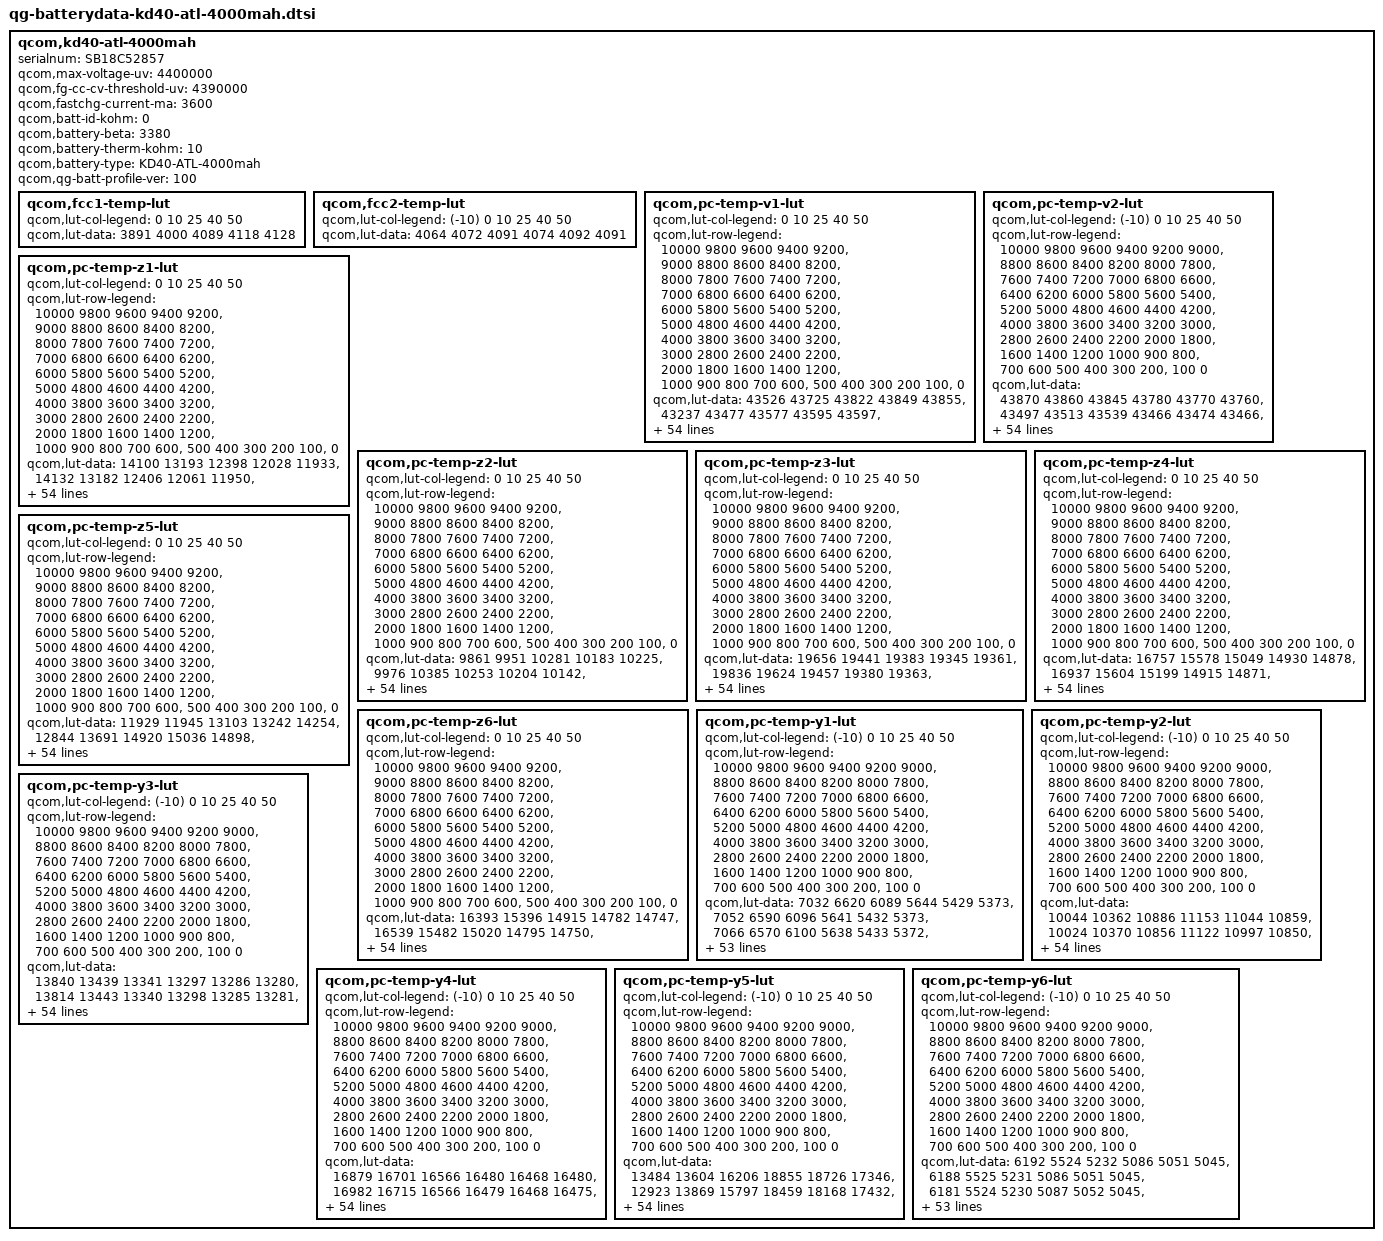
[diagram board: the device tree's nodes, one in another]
// SPDX-License-Identifier: GPL-2.0
/*
 * Copyright (c) 2018-2019, The Linux Foundation. All rights reserved.
 */

qcom,kd40-atl-4000mah {
	serialnum = "SB18C52857";
	qcom,max-voltage-uv = <4400000>;
	qcom,fg-cc-cv-threshold-uv = <4390000>;
	qcom,fastchg-current-ma = <3600>;
	qcom,batt-id-kohm = <0>;
	qcom,battery-beta = <3380>;
	qcom,battery-therm-kohm = <10>;
	qcom,battery-type = "KD40-ATL-4000mah";
	qcom,qg-batt-profile-ver = <100>;

	qcom,fcc1-temp-lut {
		qcom,lut-col-legend = <0 10 25 40 50>;
		qcom,lut-data = <3891 4000 4089 4118 4128>;
	};

	qcom,fcc2-temp-lut {
		qcom,lut-col-legend = <(-10) 0 10 25 40 50>;
		qcom,lut-data = <4064 4072 4091 4074 4092 4091>;
	};

	qcom,pc-temp-v1-lut {
		qcom,lut-col-legend = <0 10 25 40 50>;
		qcom,lut-row-legend = <10000 9800 9600 9400 9200>,
			<9000 8800 8600 8400 8200>,
			<8000 7800 7600 7400 7200>,
			<7000 6800 6600 6400 6200>,
			<6000 5800 5600 5400 5200>,
			<5000 4800 4600 4400 4200>,
			<4000 3800 3600 3400 3200>,
			<3000 2800 2600 2400 2200>,
			<2000 1800 1600 1400 1200>,
			<1000 900 800 700 600>,
			<500 400 300 200 100>,
			<0>;
		qcom,lut-data = <43526 43725 43822 43849 43855>,
			<43237 43477 43577 43595 43597>,
			<42977 43205 43334 43357 43363>,
			<42736 42949 43094 43119 43127>,
			<42502 42711 42852 42882 42892>,
			<42270 42477 42606 42643 42656>,
			<42044 42244 42365 42406 42422>,
			<41823 42013 42129 42172 42189>,
			<41606 41788 41900 41943 41959>,
			<41400 41567 41673 41717 41733>,
			<41218 41355 41449 41492 41510>,
			<41042 41166 41234 41274 41292>,
			<40834 40983 41033 41065 41076>,
			<40577 40773 40836 40865 40865>,
			<40330 40526 40626 40661 40660>,
			<40130 40297 40408 40450 40462>,
			<39954 40111 40210 40252 40272>,
			<39800 39945 40038 40078 40097>,
			<39670 39795 39877 39916 39931>,
			<39548 39661 39728 39758 39769>,
			<39423 39526 39587 39608 39617>,
			<39298 39386 39407 39433 39445>,
			<39175 39240 39148 39173 39197>,
			<39054 39066 38908 38916 38943>,
			<38936 38848 38752 38772 38793>,
			<38825 38663 38630 38673 38691>,
			<38719 38539 38533 38581 38596>,
			<38620 38442 38458 38491 38502>,
			<38526 38374 38390 38406 38412>,
			<38439 38323 38322 38326 38323>,
			<38365 38279 38259 38251 38238>,
			<38299 38236 38202 38182 38164>,
			<38245 38197 38151 38119 38102>,
			<38203 38160 38102 38061 38042>,
			<38169 38126 38058 38008 37982>,
			<38135 38092 38016 37959 37924>,
			<38104 38060 37975 37909 37865>,
			<38068 38024 37936 37861 37810>,
			<38018 37972 37884 37800 37744>,
			<37951 37889 37802 37714 37653>,
			<37867 37790 37700 37610 37546>,
			<37750 37679 37588 37500 37432>,
			<37616 37549 37459 37376 37304>,
			<37470 37391 37306 37220 37151>,
			<37335 37251 37167 37080 37017>,
			<37241 37154 37073 36994 36937>,
			<37202 37127 37043 36964 36910>,
			<37177 37111 37028 36946 36889>,
			<37148 37085 37007 36924 36864>,
			<37094 37035 36949 36850 36778>,
			<36866 36788 36689 36570 36473>,
			<36421 36348 36254 36124 36028>,
			<35836 35772 35680 35546 35448>,
			<35041 34986 34894 34755 34655>,
			<33786 33750 33659 33524 33419>,
			<30000 30000 30000 30000 30000>;
	};

	qcom,pc-temp-v2-lut {
		qcom,lut-col-legend = <(-10) 0 10 25 40 50>;
		qcom,lut-row-legend = <10000 9800 9600 9400 9200 9000>,
			<8800 8600 8400 8200 8000 7800>,
			<7600 7400 7200 7000 6800 6600>,
			<6400 6200 6000 5800 5600 5400>,
			<5200 5000 4800 4600 4400 4200>,
			<4000 3800 3600 3400 3200 3000>,
			<2800 2600 2400 2200 2000 1800>,
			<1600 1400 1200 1000 900 800>,
			<700 600 500 400 300 200>,
			<100 0>;
		qcom,lut-data = <43870 43860 43845 43780 43770 43760>,
			<43497 43513 43539 43466 43474 43466>,
			<43156 43197 43252 43174 43196 43190>,
			<42853 42915 42986 42910 42937 42934>,
			<42582 42665 42741 42669 42697 42696>,
			<42329 42423 42502 42434 42462 42461>,
			<42094 42181 42267 42199 42226 42227>,
			<41869 41946 42035 41966 41993 41994>,
			<41626 41723 41805 41737 41764 41765>,
			<41370 41509 41578 41511 41538 41539>,
			<41148 41297 41358 41291 41316 41316>,
			<40983 41089 41146 41077 41099 41097>,
			<40816 40877 40939 40867 40886 40883>,
			<40563 40652 40736 40662 40682 40679>,
			<40227 40414 40534 40458 40483 40481>,
			<39926 40163 40315 40260 40289 40289>,
			<39661 39877 40068 40063 40096 40101>,
			<39436 39616 39826 39878 39913 39922>,
			<39276 39432 39611 39722 39750 39758>,
			<39148 39283 39409 39577 39596 39599>,
			<39018 39130 39224 39397 39412 39417>,
			<38884 38969 39049 39153 39189 39201>,
			<38746 38817 38891 38923 38977 38995>,
			<38582 38678 38748 38755 38795 38809>,
			<38409 38549 38618 38614 38633 38641>,
			<38280 38428 38499 38490 38502 38506>,
			<38184 38314 38388 38383 38394 38396>,
			<38103 38208 38286 38285 38297 38297>,
			<38031 38104 38193 38195 38209 38208>,
			<37966 38010 38105 38112 38129 38127>,
			<37907 37941 38024 38039 38057 38053>,
			<37853 37888 37947 37971 37992 37984>,
			<37799 37842 37881 37911 37927 37918>,
			<37742 37802 37823 37855 37863 37857>,
			<37685 37765 37773 37803 37796 37791>,
			<37630 37726 37731 37745 37717 37701>,
			<37575 37688 37694 37683 37630 37592>,
			<37519 37640 37651 37618 37545 37492>,
			<37460 37570 37601 37551 37466 37404>,
			<37400 37488 37540 37479 37385 37319>,
			<37343 37405 37460 37400 37305 37239>,
			<37286 37314 37360 37311 37217 37154>,
			<37220 37214 37247 37194 37102 37037>,
			<37146 37111 37116 37064 36977 36912>,
			<37064 37008 36982 36942 36867 36808>,
			<36955 36903 36912 36884 36819 36763>,
			<36892 36857 36884 36868 36808 36752>,
			<36826 36809 36862 36850 36791 36733>,
			<36740 36747 36824 36820 36757 36697>,
			<36591 36641 36728 36737 36651 36570>,
			<36335 36400 36449 36449 36312 36201>,
			<35925 35965 35938 35973 35815 35692>,
			<35315 35339 35271 35348 35169 35039>,
			<34402 34453 34364 34527 34288 34145>,
			<32972 33049 33061 33271 32993 32824>,
			<28326 27783 27914 28055 27759 27662>;
	};

	qcom,pc-temp-z1-lut {
		qcom,lut-col-legend = <0 10 25 40 50>;
		qcom,lut-row-legend = <10000 9800 9600 9400 9200>,
			<9000 8800 8600 8400 8200>,
			<8000 7800 7600 7400 7200>,
			<7000 6800 6600 6400 6200>,
			<6000 5800 5600 5400 5200>,
			<5000 4800 4600 4400 4200>,
			<4000 3800 3600 3400 3200>,
			<3000 2800 2600 2400 2200>,
			<2000 1800 1600 1400 1200>,
			<1000 900 800 700 600>,
			<500 400 300 200 100>,
			<0>;
		qcom,lut-data = <14100 13193 12398 12028 11933>,
			<14132 13182 12406 12061 11950>,
			<14132 13183 12404 12055 11954>,
			<14108 13182 12394 12054 11953>,
			<14089 13171 12386 12052 11952>,
			<14070 13159 12377 12049 11952>,
			<14051 13154 12370 12047 11951>,
			<14046 13148 12362 12046 11952>,
			<14050 13141 12356 12046 11955>,
			<14055 13125 12356 12046 11958>,
			<14054 13110 12358 12048 11959>,
			<14050 13102 12359 12050 11960>,
			<14033 13097 12359 12051 11961>,
			<13967 13085 12358 12052 11963>,
			<13912 13061 12356 12052 11963>,
			<13911 13047 12352 12052 11963>,
			<13919 13050 12351 12051 11963>,
			<13917 13057 12354 12052 11965>,
			<13891 13061 12358 12054 11967>,
			<13869 13066 12362 12056 11969>,
			<13868 13072 12366 12058 11970>,
			<13869 13079 12369 12059 11970>,
			<13871 13089 12372 12060 11972>,
			<13877 13099 12376 12060 11973>,
			<13886 13112 12380 12062 11975>,
			<13894 13122 12385 12065 11976>,
			<13902 13129 12391 12069 11979>,
			<13908 13134 12397 12073 11982>,
			<13913 13136 12403 12077 11986>,
			<13918 13137 12408 12080 11989>,
			<13924 13137 12413 12084 11992>,
			<13935 13145 12418 12088 11996>,
			<13944 13158 12423 12093 12000>,
			<13951 13165 12429 12098 12004>,
			<13960 13169 12437 12102 12008>,
			<13970 13174 12447 12107 12012>,
			<14004 13186 12455 12112 12016>,
			<14035 13204 12462 12118 12019>,
			<14036 13214 12470 12122 12023>,
			<14032 13222 12477 12126 12027>,
			<14030 13229 12485 12129 12031>,
			<14045 13240 12493 12134 12033>,
			<14056 13249 12502 12138 12036>,
			<14077 13259 12509 12142 12038>,
			<14047 13282 12518 12146 12041>,
			<14053 13276 12521 12149 12044>,
			<14120 13285 12520 12150 12044>,
			<14113 13278 12521 12152 12044>,
			<14057 13280 12524 12154 12048>,
			<14057 13288 12534 12159 12054>,
			<14047 13284 12539 12164 12058>,
			<14077 13321 12547 12173 12066>,
			<14138 13357 12569 12187 12078>,
			<14107 13404 12602 12207 12096>,
			<14107 13404 12602 12207 12096>,
			<14107 13404 12602 12207 12096>;
	};

	qcom,pc-temp-z2-lut {
		qcom,lut-col-legend = <0 10 25 40 50>;
		qcom,lut-row-legend = <10000 9800 9600 9400 9200>,
			<9000 8800 8600 8400 8200>,
			<8000 7800 7600 7400 7200>,
			<7000 6800 6600 6400 6200>,
			<6000 5800 5600 5400 5200>,
			<5000 4800 4600 4400 4200>,
			<4000 3800 3600 3400 3200>,
			<3000 2800 2600 2400 2200>,
			<2000 1800 1600 1400 1200>,
			<1000 900 800 700 600>,
			<500 400 300 200 100>,
			<0>;
		qcom,lut-data = <9861 9951 10281 10183 10225>,
			<9976 10385 10253 10204 10142>,
			<10039 10206 10502 10300 10221>,
			<10084 10122 10779 10319 10280>,
			<10098 10099 10809 10324 10313>,
			<10087 10085 10494 10319 10302>,
			<10071 10080 10241 10307 10277>,
			<10065 10077 10209 10283 10256>,
			<10062 10073 10191 10242 10233>,
			<10060 10065 10189 10225 10215>,
			<10060 10059 10198 10234 10199>,
			<10059 10087 10215 10242 10186>,
			<10055 10148 10360 10205 10189>,
			<10042 10159 10542 10128 10207>,
			<10030 10103 10515 10110 10206>,
			<10025 10056 10322 10147 10178>,
			<10022 10067 10232 10172 10158>,
			<10022 10090 10242 10152 10144>,
			<10036 10112 10256 10127 10118>,
			<10051 10137 10269 10136 10117>,
			<10055 10158 10289 10165 10134>,
			<10056 10172 10316 10206 10159>,
			<10054 10183 10366 10312 10232>,
			<10037 10197 10401 10413 10316>,
			<10018 10217 10380 10372 10308>,
			<10016 10230 10336 10227 10240>,
			<10017 10232 10320 10172 10210>,
			<10019 10233 10314 10191 10229>,
			<10025 10231 10313 10220 10261>,
			<10032 10226 10326 10259 10305>,
			<10039 10222 10348 10304 10362>,
			<10046 10222 10354 10320 10366>,
			<10053 10223 10357 10324 10269>,
			<10058 10225 10359 10324 10180>,
			<10063 10230 10367 10305 10146>,
			<10071 10236 10378 10280 10122>,
			<10087 10245 10385 10279 10134>,
			<10105 10256 10391 10296 10187>,
			<10119 10267 10400 10317 10233>,
			<10132 10279 10420 10347 10260>,
			<10146 10289 10442 10374 10281>,
			<10160 10296 10455 10374 10294>,
			<10182 10303 10464 10363 10303>,
			<10230 10313 10447 10398 10283>,
			<10402 10415 10461 10406 10263>,
			<10293 10524 10508 10338 10253>,
			<10302 10558 10499 10320 10265>,
			<10292 10713 10500 10339 10269>,
			<10278 10727 10534 10359 10300>,
			<10218 10834 10559 10405 10334>,
			<10205 10760 10578 10367 10183>,
			<10099 10688 10526 10207 10063>,
			<9986 10508 10507 10157 10009>,
			<9834 10354 10442 10097 9939>,
			<9834 10354 10442 10097 9939>,
			<9834 10354 10442 10097 9939>;
	};

	qcom,pc-temp-z3-lut {
		qcom,lut-col-legend = <0 10 25 40 50>;
		qcom,lut-row-legend = <10000 9800 9600 9400 9200>,
			<9000 8800 8600 8400 8200>,
			<8000 7800 7600 7400 7200>,
			<7000 6800 6600 6400 6200>,
			<6000 5800 5600 5400 5200>,
			<5000 4800 4600 4400 4200>,
			<4000 3800 3600 3400 3200>,
			<3000 2800 2600 2400 2200>,
			<2000 1800 1600 1400 1200>,
			<1000 900 800 700 600>,
			<500 400 300 200 100>,
			<0>;
		qcom,lut-data = <19656 19441 19383 19345 19361>,
			<19836 19624 19457 19380 19363>,
			<19840 19689 19482 19412 19397>,
			<19801 19699 19495 19423 19413>,
			<19769 19701 19499 19432 19422>,
			<19746 19701 19501 19442 19430>,
			<19731 19701 19502 19449 19435>,
			<19729 19700 19500 19448 19436>,
			<19730 19696 19497 19445 19436>,
			<19731 19685 19493 19441 19435>,
			<19731 19674 19484 19434 19427>,
			<19731 19668 19478 19425 19416>,
			<19733 19666 19481 19413 19412>,
			<19743 19664 19489 19399 19409>,
			<19751 19647 19486 19396 19406>,
			<19748 19628 19471 19400 19401>,
			<19738 19607 19459 19402 19395>,
			<19723 19583 19449 19397 19387>,
			<19693 19570 19440 19388 19377>,
			<19668 19559 19435 19382 19370>,
			<19668 19554 19431 19377 19365>,
			<19675 19558 19431 19375 19363>,
			<19685 19567 19451 19385 19368>,
			<19719 19579 19467 19396 19376>,
			<19759 19599 19463 19390 19370>,
			<19777 19612 19452 19368 19347>,
			<19787 19611 19444 19360 19337>,
			<19792 19610 19437 19360 19343>,
			<19793 19608 19434 19360 19354>,
			<19793 19602 19435 19367 19373>,
			<19792 19595 19438 19381 19399>,
			<19787 19589 19440 19392 19406>,
			<19779 19582 19443 19400 19399>,
			<19767 19577 19446 19404 19391>,
			<19751 19574 19447 19401 19384>,
			<19734 19569 19448 19394 19377>,
			<19711 19562 19446 19389 19371>,
			<19692 19553 19439 19383 19366>,
			<19683 19550 19434 19379 19362>,
			<19678 19551 19431 19375 19358>,
			<19674 19550 19429 19373 19355>,
			<19670 19542 19426 19371 19357>,
			<19664 19531 19424 19370 19364>,
			<19636 19527 19421 19374 19369>,
			<19519 19497 19410 19374 19368>,
			<19357 19466 19394 19358 19352>,
			<19350 19446 19394 19358 19342>,
			<19324 19356 19372 19350 19337>,
			<19323 19383 19366 19344 19330>,
			<19314 19344 19359 19339 19333>,
			<19324 19366 19365 19352 19369>,
			<19330 19378 19363 19366 19369>,
			<19358 19361 19352 19367 19372>,
			<19364 19353 19352 19368 19372>,
			<19364 19353 19352 19368 19372>,
			<19364 19353 19352 19368 19372>;
	};

	qcom,pc-temp-z4-lut {
		qcom,lut-col-legend = <0 10 25 40 50>;
		qcom,lut-row-legend = <10000 9800 9600 9400 9200>,
			<9000 8800 8600 8400 8200>,
			<8000 7800 7600 7400 7200>,
			<7000 6800 6600 6400 6200>,
			<6000 5800 5600 5400 5200>,
			<5000 4800 4600 4400 4200>,
			<4000 3800 3600 3400 3200>,
			<3000 2800 2600 2400 2200>,
			<2000 1800 1600 1400 1200>,
			<1000 900 800 700 600>,
			<500 400 300 200 100>,
			<0>;
		qcom,lut-data = <16757 15578 15049 14930 14878>,
			<16937 15604 15199 14915 14871>,
			<16865 15563 15167 14976 14916>,
			<16580 15498 15046 14932 14889>,
			<16311 15349 14974 14888 14857>,
			<16108 15202 14933 14854 14832>,
			<15927 15108 14899 14825 14808>,
			<15780 15032 14867 14802 14786>,
			<15654 14976 14837 14783 14765>,
			<15548 14935 14812 14769 14751>,
			<15460 14899 14791 14756 14744>,
			<15384 14854 14771 14748 14738>,
			<15322 14808 14741 14745 14731>,
			<15272 14789 14714 14743 14723>,
			<15225 14792 14712 14739 14718>,
			<15177 14799 14726 14730 14714>,
			<15131 14796 14731 14720 14711>,
			<15098 14788 14723 14712 14707>,
			<15077 14780 14713 14703 14704>,
			<15057 14766 14705 14700 14701>,
			<15029 14752 14697 14698 14698>,
			<14993 14739 14700 14698 14696>,
			<14954 14729 14758 14761 14753>,
			<14904 14735 14817 14840 14834>,
			<14858 14784 14837 14855 14854>,
			<14835 14821 14850 14860 14860>,
			<14820 14829 14851 14860 14861>,
			<14812 14833 14836 14847 14842>,
			<14809 14831 14818 14826 14810>,
			<14808 14815 14801 14801 14775>,
			<14807 14797 14782 14771 14734>,
			<14805 14783 14764 14746 14714>,
			<14804 14770 14746 14723 14705>,
			<14802 14758 14731 14709 14700>,
			<14800 14747 14718 14704 14699>,
			<14799 14738 14708 14701 14698>,
			<14801 14731 14703 14700 14698>,
			<14802 14725 14700 14699 14699>,
			<14798 14723 14699 14699 14700>,
			<14784 14722 14704 14710 14712>,
			<14775 14721 14710 14722 14727>,
			<14770 14724 14707 14720 14723>,
			<14767 14726 14702 14712 14710>,
			<14770 14722 14703 14710 14711>,
			<14810 14711 14697 14704 14707>,
			<14934 14701 14678 14683 14683>,
			<14936 14713 14669 14674 14681>,
			<14956 14807 14679 14663 14667>,
			<14950 14766 14672 14647 14645>,
			<14948 14804 14679 14650 14641>,
			<14940 14794 14696 14677 14658>,
			<14962 14796 14711 14678 14672>,
			<14957 14826 14729 14683 14674>,
			<14977 14850 14736 14686 14678>,
			<14977 14850 14736 14686 14678>,
			<14977 14850 14736 14686 14678>;
	};

	qcom,pc-temp-z5-lut {
		qcom,lut-col-legend = <0 10 25 40 50>;
		qcom,lut-row-legend = <10000 9800 9600 9400 9200>,
			<9000 8800 8600 8400 8200>,
			<8000 7800 7600 7400 7200>,
			<7000 6800 6600 6400 6200>,
			<6000 5800 5600 5400 5200>,
			<5000 4800 4600 4400 4200>,
			<4000 3800 3600 3400 3200>,
			<3000 2800 2600 2400 2200>,
			<2000 1800 1600 1400 1200>,
			<1000 900 800 700 600>,
			<500 400 300 200 100>,
			<0>;
		qcom,lut-data = <11929 11945 13103 13242 14254>,
			<12844 13691 14920 15036 14898>,
			<13167 14619 15415 16148 16503>,
			<13323 15060 15769 16769 17691>,
			<13484 15307 16141 17420 18689>,
			<13691 15570 16687 18414 19595>,
			<13895 16064 17187 19279 20420>,
			<14068 16649 17559 19596 21280>,
			<14225 17095 17911 19780 22214>,
			<14356 17444 18222 19863 22571>,
			<14457 17687 18656 20003 22189>,
			<14542 18545 19324 20120 21754>,
			<14632 20063 22055 19598 21968>,
			<14749 20649 25238 18434 22768>,
			<14830 20927 25018 18383 23389>,
			<14843 20801 22389 20254 23859>,
			<14848 19870 21144 21690 24119>,
			<14823 18764 21267 21672 23572>,
			<14508 18660 21502 21493 22496>,
			<14199 19110 22072 21783 22303>,
			<14271 19829 23496 22354 22756>,
			<14675 21769 26712 23310 23435>,
			<15324 25594 39639 27194 24922>,
			<17153 31801 49817 31251 26468>,
			<19789 44390 44871 29094 24879>,
			<22249 52101 33750 21259 18519>,
			<24810 50038 27699 17431 15638>,
			<27197 45580 24122 16554 15586>,
			<29693 41641 22559 16160 15586>,
			<31762 37728 22549 16618 17376>,
			<32162 34567 22576 18014 21820>,
			<32160 32310 22879 19903 23895>,
			<32149 30636 24322 23163 24705>,
			<30993 30047 26255 25996 25074>,
			<28176 29839 29703 27726 25805>,
			<25646 29619 32873 28920 26965>,
			<23052 28760 32988 29050 27100>,
			<21319 27595 32175 28876 26936>,
			<21380 27627 31271 28573 26626>,
			<22002 29375 30325 27037 24497>,
			<22731 30602 29304 24874 22087>,
			<23985 27907 28165 23210 22035>,
			<24571 25036 27024 21945 22674>,
			<22842 25692 25695 23169 23855>,
			<18316 24770 24858 23834 24141>,
			<12477 22683 23349 21022 20529>,
			<12345 19724 23506 21214 18173>,
			<11899 13085 18416 20206 18412>,
			<11878 14716 17908 21181 20274>,
			<11802 12901 17087 19879 21423>,
			<12018 13676 17002 17829 23841>,
			<11930 13781 15606 18088 19764>,
			<12141 12873 14253 17108 18434>,
			<11942 12386 13854 16243 16818>,
			<11942 12386 13854 16243 16818>,
			<11942 12386 13854 16243 16818>;
	};

	qcom,pc-temp-z6-lut {
		qcom,lut-col-legend = <0 10 25 40 50>;
		qcom,lut-row-legend = <10000 9800 9600 9400 9200>,
			<9000 8800 8600 8400 8200>,
			<8000 7800 7600 7400 7200>,
			<7000 6800 6600 6400 6200>,
			<6000 5800 5600 5400 5200>,
			<5000 4800 4600 4400 4200>,
			<4000 3800 3600 3400 3200>,
			<3000 2800 2600 2400 2200>,
			<2000 1800 1600 1400 1200>,
			<1000 900 800 700 600>,
			<500 400 300 200 100>,
			<0>;
		qcom,lut-data = <16393 15396 14915 14782 14747>,
			<16539 15482 15020 14795 14750>,
			<16502 15491 15013 14834 14785>,
			<16340 15480 14971 14823 14782>,
			<16189 15406 14943 14811 14777>,
			<16078 15329 14924 14801 14771>,
			<15982 15283 14908 14793 14764>,
			<15907 15244 14892 14783 14756>,
			<15846 15213 14876 14774 14749>,
			<15795 15186 14862 14765 14742>,
			<15753 15162 14849 14756 14734>,
			<15716 15139 14838 14748 14726>,
			<15680 15118 14828 14740 14720>,
			<15645 15101 14820 14732 14715>,
			<15612 15087 14815 14728 14711>,
			<15583 15074 14812 14725 14706>,
			<15557 15061 14807 14722 14702>,
			<15532 15049 14799 14715 14695>,
			<15506 15038 14790 14707 14688>,
			<15485 15028 14784 14702 14683>,
			<15470 15023 14780 14698 14679>,
			<15458 15023 14782 14698 14677>,
			<15454 15024 14819 14731 14705>,
			<15455 15031 14852 14771 14745>,
			<15457 15064 14856 14773 14748>,
			<15459 15089 14858 14766 14742>,
			<15461 15094 14857 14760 14735>,
			<15463 15097 14849 14754 14730>,
			<15465 15096 14839 14748 14724>,
			<15467 15088 14833 14743 14721>,
			<15467 15079 14828 14738 14717>,
			<15467 15072 14823 14733 14713>,
			<15465 15065 14817 14728 14707>,
			<15462 15060 14813 14724 14700>,
			<15455 15056 14810 14721 14696>,
			<15449 15053 14808 14717 14692>,
			<15443 15049 14804 14714 14689>,
			<15439 15046 14801 14710 14686>,
			<15436 15046 14799 14709 14685>,
			<15435 15051 14801 14712 14689>,
			<15434 15054 14804 14716 14693>,
			<15436 15054 14803 14714 14693>,
			<15437 15054 14801 14711 14692>,
			<15432 15054 14801 14713 14694>,
			<15396 15042 14795 14711 14692>,
			<15374 15026 14780 14694 14674>,
			<15370 15022 14777 14690 14669>,
			<15366 15016 14770 14681 14660>,
			<15365 15014 14764 14671 14647>,
			<15365 15015 14765 14671 14647>,
			<15378 15028 14777 14691 14674>,
			<15400 15043 14787 14701 14684>,
			<15430 15059 14793 14707 14689>,
			<15468 15084 14804 14714 14696>,
			<15468 15084 14804 14714 14696>,
			<15468 15084 14804 14714 14696>;
	};

	qcom,pc-temp-y1-lut {
		qcom,lut-col-legend = <(-10) 0 10 25 40 50>;
		qcom,lut-row-legend = <10000 9800 9600 9400 9200 9000>,
			<8800 8600 8400 8200 8000 7800>,
			<7600 7400 7200 7000 6800 6600>,
			<6400 6200 6000 5800 5600 5400>,
			<5200 5000 4800 4600 4400 4200>,
			<4000 3800 3600 3400 3200 3000>,
			<2800 2600 2400 2200 2000 1800>,
			<1600 1400 1200 1000 900 800>,
			<700 600 500 400 300 200>,
			<100 0>;
		qcom,lut-data = <7032 6620 6089 5644 5429 5373>,
			<7052 6590 6096 5641 5432 5373>,
			<7066 6570 6100 5638 5433 5372>,
			<7077 6558 6101 5635 5433 5372>,
			<7083 6553 6099 5633 5433 5372>,
			<7084 6551 6095 5630 5433 5371>,
			<7079 6549 6087 5628 5431 5371>,
			<7072 6546 6078 5626 5429 5371>,
			<7075 6543 6077 5624 5428 5371>,
			<7088 6540 6077 5622 5427 5369>,
			<7096 6537 6075 5621 5427 5368>,
			<7100 6531 6065 5620 5427 5369>,
			<7102 6524 6055 5619 5427 5370>,
			<7105 6520 6055 5619 5427 5370>,
			<7112 6517 6058 5618 5427 5370>,
			<7114 6519 6059 5618 5427 5370>,
			<7115 6533 6060 5620 5430 5371>,
			<7115 6546 6062 5623 5432 5372>,
			<7111 6542 6067 5625 5432 5372>,
			<7106 6533 6075 5627 5433 5373>,
			<7110 6530 6075 5629 5433 5373>,
			<7120 6534 6068 5633 5433 5374>,
			<7127 6538 6063 5636 5434 5375>,
			<7123 6539 6068 5640 5435 5377>,
			<7111 6540 6077 5644 5437 5379>,
			<7099 6542 6081 5648 5440 5382>,
			<7085 6557 6080 5653 5444 5385>,
			<7074 6567 6080 5658 5447 5387>,
			<7072 6558 6080 5663 5450 5389>,
			<7072 6543 6081 5669 5454 5391>,
			<7070 6540 6084 5673 5457 5393>,
			<7067 6548 6091 5677 5460 5397>,
			<7063 6552 6098 5682 5463 5399>,
			<7057 6545 6108 5686 5466 5402>,
			<7051 6535 6115 5690 5469 5404>,
			<7056 6535 6114 5695 5471 5405>,
			<7072 6543 6111 5700 5473 5406>,
			<7081 6546 6110 5703 5475 5407>,
			<7060 6541 6114 5705 5476 5409>,
			<7031 6535 6118 5707 5478 5410>,
			<7017 6531 6122 5708 5479 5412>,
			<7002 6525 6126 5710 5481 5414>,
			<7026 6523 6132 5714 5483 5415>,
			<7040 6529 6144 5722 5486 5417>,
			<7043 6567 6161 5728 5493 5422>,
			<7076 6577 6162 5733 5496 5424>,
			<7052 6582 6166 5739 5497 5424>,
			<7062 6578 6181 5739 5497 5424>,
			<7058 6600 6162 5741 5496 5424>,
			<7091 6557 6175 5740 5496 5425>,
			<7071 6554 6172 5742 5501 5428>,
			<7065 6597 6205 5756 5507 5434>,
			<7088 6580 6210 5781 5518 5443>,
			<7176 6653 6234 5806 5532 5454>,
			<7176 6653 6234 5806 5532 5454>,
			<7176 6653 6234 5806 5532 5454>;
	};

	qcom,pc-temp-y2-lut {
		qcom,lut-col-legend = <(-10) 0 10 25 40 50>;
		qcom,lut-row-legend = <10000 9800 9600 9400 9200 9000>,
			<8800 8600 8400 8200 8000 7800>,
			<7600 7400 7200 7000 6800 6600>,
			<6400 6200 6000 5800 5600 5400>,
			<5200 5000 4800 4600 4400 4200>,
			<4000 3800 3600 3400 3200 3000>,
			<2800 2600 2400 2200 2000 1800>,
			<1600 1400 1200 1000 900 800>,
			<700 600 500 400 300 200>,
			<100 0>;
		qcom,lut-data = <10044 10362 10886 11153 11044 10859>,
			<10024 10370 10856 11122 10997 10850>,
			<10021 10380 10824 11075 10943 10839>,
			<10029 10391 10793 11023 10892 10827>,
			<10046 10404 10766 10978 10852 10813>,
			<10068 10418 10745 10953 10832 10799>,
			<10097 10436 10726 10938 10827 10768>,
			<10137 10453 10712 10925 10827 10733>,
			<10216 10457 10713 10918 10821 10718>,
			<10354 10458 10718 10901 10803 10709>,
			<10420 10462 10721 10894 10805 10708>,
			<10425 10519 10725 10895 10836 10712>,
			<10429 10603 10732 10897 10862 10718>,
			<10461 10670 10762 10903 10854 10726>,
			<10549 10733 10827 10916 10830 10740>,
			<10620 10751 10873 10934 10829 10759>,
			<10670 10744 10905 10964 10903 10790>,
			<10706 10737 10922 11006 10991 10832>,
			<10726 10753 10921 11077 11055 10920>,
			<10740 10798 10917 11166 11108 11042>,
			<10743 10835 10920 11181 11117 11106>,
			<10730 10866 10943 11116 11113 11146>,
			<10703 10891 10970 11065 11104 11163>,
			<10410 10912 10997 11075 11048 11081>,
			<9860 10929 11022 11097 10973 10960>,
			<9702 10929 11033 11114 10972 10947>,
			<9692 10912 11040 11128 11020 10978>,
			<9686 10899 11047 11144 11063 11005>,
			<9680 10905 11063 11164 11112 11055>,
			<9675 10914 11078 11183 11155 11108>,
			<9673 10914 11078 11191 11166 11119>,
			<9672 10900 11074 11195 11196 11144>,
			<9671 10884 11071 11199 11212 11164>,
			<9669 10870 11070 11210 11213 11222>,
			<9668 10854 11068 11221 11205 11274>,
			<9666 10837 11063 11213 11162 11247>,
			<9665 10819 11053 11186 11078 11168>,
			<9664 10771 11040 11170 11036 11103>,
			<9663 10334 11024 11166 11017 11047>,
			<9662 9841 11004 11161 11009 11004>,
			<9661 9734 10972 11150 11017 10983>,
			<9661 9694 10934 11132 11027 10970>,
			<9660 9679 10904 11095 11044 10932>,
			<9659 9671 10851 11081 11028 10902>,
			<9659 9670 10817 11105 10954 10816>,
			<9659 9666 10747 11039 10861 10745>,
			<9658 9663 10715 11028 10890 10712>,
			<9658 9661 10679 11017 10900 10757>,
			<9657 9659 10645 11037 10928 10783>,
			<9657 9658 10609 11022 10927 10724>,
			<9656 9656 10549 11023 10879 10678>,
			<9655 9655 10346 10974 10842 10638>,
			<9653 9654 9839 10901 10737 10537>,
			<9650 9653 9684 10837 10624 10469>,
			<9650 9653 9684 10837 10624 10469>,
			<9650 9653 9684 10837 10624 10469>;
	};

	qcom,pc-temp-y3-lut {
		qcom,lut-col-legend = <(-10) 0 10 25 40 50>;
		qcom,lut-row-legend = <10000 9800 9600 9400 9200 9000>,
			<8800 8600 8400 8200 8000 7800>,
			<7600 7400 7200 7000 6800 6600>,
			<6400 6200 6000 5800 5600 5400>,
			<5200 5000 4800 4600 4400 4200>,
			<4000 3800 3600 3400 3200 3000>,
			<2800 2600 2400 2200 2000 1800>,
			<1600 1400 1200 1000 900 800>,
			<700 600 500 400 300 200>,
			<100 0>;
		qcom,lut-data = <13840 13439 13341 13297 13286 13280>,
			<13814 13443 13340 13298 13285 13281>,
			<13790 13446 13340 13299 13285 13282>,
			<13767 13449 13341 13300 13285 13283>,
			<13748 13451 13343 13301 13286 13283>,
			<13732 13451 13345 13301 13286 13284>,
			<13722 13451 13349 13302 13287 13285>,
			<13713 13450 13352 13303 13289 13285>,
			<13699 13452 13353 13304 13289 13286>,
			<13680 13459 13353 13304 13290 13288>,
			<13651 13462 13353 13305 13291 13289>,
			<13575 13462 13356 13308 13295 13289>,
			<13504 13461 13360 13311 13298 13290>,
			<13504 13453 13362 13312 13298 13292>,
			<13522 13433 13364 13311 13299 13295>,
			<13526 13421 13365 13311 13299 13296>,
			<13488 13418 13361 13310 13300 13296>,
			<13446 13414 13356 13309 13300 13295>,
			<13436 13407 13351 13311 13299 13296>,
			<13431 13398 13345 13315 13297 13297>,
			<13429 13390 13340 13315 13295 13297>,
			<13430 13385 13335 13309 13292 13293>,
			<13430 13379 13333 13303 13290 13288>,
			<13429 13373 13332 13301 13287 13285>,
			<13427 13367 13331 13299 13284 13281>,
			<13426 13366 13330 13298 13283 13281>,
			<13425 13367 13329 13297 13283 13280>,
			<13424 13367 13328 13296 13283 13280>,
			<13426 13361 13327 13297 13283 13281>,
			<13431 13352 13326 13297 13284 13282>,
			<13440 13350 13326 13297 13284 13282>,
			<13457 13351 13326 13297 13285 13281>,
			<13474 13351 13326 13298 13286 13281>,
			<13486 13355 13326 13299 13286 13283>,
			<13497 13360 13326 13300 13286 13284>,
			<13515 13364 13327 13300 13286 13284>,
			<13543 13368 13329 13299 13285 13282>,
			<13575 13370 13331 13299 13285 13281>,
			<13610 13372 13333 13299 13285 13282>,
			<13648 13374 13334 13299 13285 13283>,
			<13693 13383 13333 13299 13286 13285>,
			<13743 13403 13332 13300 13287 13286>,
			<13794 13416 13333 13299 13288 13286>,
			<13843 13437 13333 13297 13286 13284>,
			<13839 13447 13324 13295 13285 13284>,
			<13858 13491 13330 13296 13289 13289>,
			<13921 13546 13333 13299 13295 13293>,
			<13993 13620 13343 13304 13299 13296>,
			<14067 13708 13353 13309 13301 13297>,
			<14152 13814 13359 13311 13298 13294>,
			<14291 13941 13362 13305 13294 13291>,
			<14486 14121 13365 13306 13297 13292>,
			<14959 14315 13391 13312 13301 13299>,
			<16186 14632 13507 13326 13308 13308>,
			<16186 14632 13507 13326 13308 13308>,
			<16186 14632 13507 13326 13308 13308>;
	};

	qcom,pc-temp-y4-lut {
		qcom,lut-col-legend = <(-10) 0 10 25 40 50>;
		qcom,lut-row-legend = <10000 9800 9600 9400 9200 9000>,
			<8800 8600 8400 8200 8000 7800>,
			<7600 7400 7200 7000 6800 6600>,
			<6400 6200 6000 5800 5600 5400>,
			<5200 5000 4800 4600 4400 4200>,
			<4000 3800 3600 3400 3200 3000>,
			<2800 2600 2400 2200 2000 1800>,
			<1600 1400 1200 1000 900 800>,
			<700 600 500 400 300 200>,
			<100 0>;
		qcom,lut-data = <16879 16701 16566 16480 16468 16480>,
			<16982 16715 16566 16479 16468 16475>,
			<17061 16729 16567 16479 16469 16472>,
			<17115 16743 16568 16480 16470 16471>,
			<17147 16754 16569 16483 16471 16470>,
			<17156 16762 16570 16485 16472 16470>,
			<17134 16767 16571 16488 16474 16471>,
			<17097 16771 16574 16493 16476 16473>,
			<17064 16772 16580 16499 16479 16474>,
			<17029 16772 16593 16507 16483 16476>,
			<17020 16773 16605 16514 16486 16478>,
			<17185 16786 16612 16519 16487 16482>,
			<17370 16808 16622 16524 16489 16486>,
			<17299 16834 16645 16536 16494 16489>,
			<17039 16865 16681 16556 16504 16491>,
			<16907 16869 16691 16575 16515 16495>,
			<16876 16767 16674 16594 16524 16503>,
			<16858 16672 16649 16610 16536 16514>,
			<16850 16670 16615 16623 16562 16532>,
			<16845 16674 16574 16634 16593 16552>,
			<16833 16674 16554 16629 16594 16555>,
			<16794 16663 16543 16567 16559 16540>,
			<16762 16650 16536 16508 16522 16522>,
			<16757 16643 16531 16490 16495 16497>,
			<16754 16636 16527 16478 16475 16475>,
			<16754 16624 16527 16477 16472 16472>,
			<16757 16597 16528 16479 16474 16473>,
			<16760 16578 16529 16483 16477 16475>,
			<16762 16574 16531 16486 16483 16480>,
			<16764 16571 16532 16491 16492 16488>,
			<16763 16572 16530 16497 16501 16497>,
			<16755 16579 16524 16504 16512 16510>,
			<16750 16585 16521 16510 16517 16518>,
			<16754 16591 16523 16515 16519 16524>,
			<16761 16596 16527 16518 16519 16528>,
			<16763 16603 16534 16517 16513 16519>,
			<16764 16612 16543 16510 16495 16496>,
			<16765 16624 16552 16503 16486 16485>,
			<16777 16655 16561 16498 16482 16481>,
			<16795 16682 16565 16495 16481 16479>,
			<16810 16684 16565 16496 16485 16485>,
			<16824 16683 16564 16499 16491 16493>,
			<16846 16682 16559 16496 16483 16484>,
			<16859 16681 16550 16488 16472 16469>,
			<16820 16675 16527 16470 16455 16450>,
			<16789 16683 16537 16483 16470 16472>,
			<16800 16700 16554 16495 16489 16502>,
			<16814 16723 16574 16514 16518 16537>,
			<16827 16756 16608 16543 16551 16566>,
			<16830 16798 16640 16566 16557 16559>,
			<16821 16799 16631 16517 16489 16485>,
			<16805 16773 16615 16507 16478 16482>,
			<16861 16764 16674 16517 16485 16486>,
			<17177 16812 16735 16564 16514 16510>,
			<17177 16812 16735 16564 16514 16510>,
			<17177 16812 16735 16564 16514 16510>;
	};

	qcom,pc-temp-y5-lut {
		qcom,lut-col-legend = <(-10) 0 10 25 40 50>;
		qcom,lut-row-legend = <10000 9800 9600 9400 9200 9000>,
			<8800 8600 8400 8200 8000 7800>,
			<7600 7400 7200 7000 6800 6600>,
			<6400 6200 6000 5800 5600 5400>,
			<5200 5000 4800 4600 4400 4200>,
			<4000 3800 3600 3400 3200 3000>,
			<2800 2600 2400 2200 2000 1800>,
			<1600 1400 1200 1000 900 800>,
			<700 600 500 400 300 200>,
			<100 0>;
		qcom,lut-data = <13484 13604 16206 18855 18726 17346>,
			<12923 13869 15797 18459 18168 17432>,
			<12681 14179 15576 18035 17565 17442>,
			<12686 14491 15497 17616 16990 17392>,
			<12866 14766 15512 17239 16514 17298>,
			<13156 14964 15580 16938 16210 17170>,
			<14042 15079 15853 16576 16059 16798>,
			<15013 15210 16144 16133 15930 16336>,
			<15139 15809 16037 15645 15662 16090>,
			<15064 17306 15606 15081 15260 15926>,
			<14972 17935 15451 14876 15145 15724>,
			<14660 17178 15990 15082 15770 15356>,
			<14338 16356 16770 15305 16394 15078>,
			<15924 17070 17306 15062 16079 15314>,
			<20642 19267 17807 14360 15231 15918>,
			<22296 20274 18764 14135 14903 16039>,
			<18595 20444 21353 14672 14842 15336>,
			<14955 20469 23235 15667 14816 14756>,
			<15120 19906 22733 18278 14857 14803>,
			<16201 18766 21523 22344 14996 14987>,
			<17493 18376 20579 23414 15666 15638>,
			<19488 18538 19723 23015 18671 18231>,
			<20837 18708 19300 22498 20616 19899>,
			<18923 18818 19483 21809 19780 19415>,
			<14846 19076 19768 20859 18315 18459>,
			<13299 19695 19769 20154 17479 17572>,
			<12863 21751 19623 19392 16895 16571>,
			<12675 23044 19553 18976 16601 16143>,
			<12646 20758 19814 18924 16621 16229>,
			<12631 17247 20288 18898 16767 16327>,
			<12686 16608 20848 19009 17013 16205>,
			<12994 16571 21588 19658 17609 15820>,
			<13189 16576 21824 20493 18248 15761>,
			<13069 17329 21263 21834 18974 17413>,
			<12879 18484 20695 23045 19599 19190>,
			<12857 19260 20842 22981 19987 19645>,
			<12956 20048 21336 22340 20376 19938>,
			<12999 20275 21719 21913 20425 19992>,
			<12834 17855 22041 21484 19992 19786>,
			<12643 15026 22221 21074 19462 19589>,
			<12718 14485 21216 20784 19016 19631>,
			<12989 14286 19834 20219 18737 19942>,
			<13039 13938 19801 19486 20251 21422>,
			<13088 13769 19194 18808 19352 20375>,
			<13639 13555 16895 18795 18433 19310>,
			<13745 13319 16913 17050 16688 16870>,
			<13846 13506 16365 16808 17534 16599>,
			<14224 13920 17313 17074 17508 15853>,
			<14604 14271 17931 17687 16924 15709>,
			<14508 14500 18041 17819 16326 15358>,
			<14408 14218 18067 17472 17110 16472>,
			<14040 14132 16799 18589 19086 15981>,
			<12881 13896 14664 19743 20030 18752>,
			<11346 13254 14574 23975 23251 23888>,
			<11346 13254 14574 23975 23251 23888>,
			<11346 13254 14574 23975 23251 23888>;
	};

	qcom,pc-temp-y6-lut {
		qcom,lut-col-legend = <(-10) 0 10 25 40 50>;
		qcom,lut-row-legend = <10000 9800 9600 9400 9200 9000>,
			<8800 8600 8400 8200 8000 7800>,
			<7600 7400 7200 7000 6800 6600>,
			<6400 6200 6000 5800 5600 5400>,
			<5200 5000 4800 4600 4400 4200>,
			<4000 3800 3600 3400 3200 3000>,
			<2800 2600 2400 2200 2000 1800>,
			<1600 1400 1200 1000 900 800>,
			<700 600 500 400 300 200>,
			<100 0>;
		qcom,lut-data = <6192 5524 5232 5086 5051 5045>,
			<6188 5525 5231 5086 5051 5045>,
			<6181 5524 5230 5087 5052 5045>,
			<6170 5522 5228 5088 5052 5045>,
			<6158 5520 5227 5089 5053 5045>,
			<6143 5517 5227 5090 5054 5046>,
			<6126 5512 5227 5091 5055 5047>,
			<6107 5508 5227 5093 5056 5048>,
			<6084 5507 5228 5095 5058 5049>,
			<6057 5506 5229 5097 5060 5050>,
			<6046 5506 5232 5100 5062 5052>,
			<6046 5508 5234 5103 5064 5053>,
			<6047 5509 5238 5106 5067 5055>,
			<6031 5508 5245 5111 5069 5057>,
			<5983 5505 5255 5116 5072 5060>,
			<5945 5499 5257 5121 5075 5063>,
			<5917 5474 5251 5125 5078 5065>,
			<5899 5450 5241 5130 5082 5067>,
			<5899 5444 5228 5135 5088 5073>,
			<5900 5441 5212 5140 5095 5079>,
			<5901 5438 5203 5139 5095 5080>,
			<5899 5434 5196 5117 5083 5072>,
			<5897 5431 5193 5096 5070 5063>,
			<5890 5431 5192 5090 5060 5053>,
			<5878 5431 5192 5086 5052 5045>,
			<5876 5432 5192 5085 5051 5044>,
			<5885 5434 5193 5086 5052 5044>,
			<5898 5437 5194 5087 5052 5045>,
			<5911 5441 5196 5088 5055 5047>,
			<5926 5447 5199 5091 5058 5050>,
			<5942 5456 5201 5093 5061 5053>,
			<5959 5470 5202 5096 5065 5056>,
			<5978 5487 5204 5099 5068 5058>,
			<5997 5504 5207 5102 5069 5062>,
			<6019 5524 5212 5105 5069 5064>,
			<6044 5544 5217 5104 5067 5061>,
			<6072 5566 5225 5102 5062 5053>,
			<6104 5589 5233 5101 5059 5050>,
			<6138 5613 5241 5100 5059 5050>,
			<6176 5640 5249 5100 5059 5050>,
			<6219 5671 5255 5101 5061 5053>,
			<6265 5707 5262 5103 5063 5057>,
			<6313 5751 5271 5102 5062 5054>,
			<6360 5807 5279 5100 5058 5048>,
			<6363 5830 5268 5095 5052 5044>,
			<6380 5895 5294 5101 5061 5054>,
			<6434 5960 5313 5107 5070 5066>,
			<6495 6040 5340 5116 5082 5078>,
			<6558 6131 5373 5129 5092 5087>,
			<6631 6238 5405 5137 5092 5083>,
			<6739 6351 5427 5119 5070 5060>,
			<6894 6492 5473 5120 5070 5060>,
			<7328 6647 5587 5132 5077 5068>,
			<8460 6941 5766 5161 5092 5084>,
			<8460 6941 5766 5161 5092 5084>,
			<8460 6941 5766 5161 5092 5084>;
	};

};
